# STM32H743 register map
File version: 2.4
CPU: CM7 r0p1, little endian, MPU, FPU, 4 interrupt priority bits
Registers are 32-bit, read-write, reset 0x0 unless marked. A register's access mark holds for its fields unless they carry their own. Offsets are from the block's base; [hi:lo] are bit positions; {n}, {i} and the like mark numbered series.

## ADC3 — 模数转换器
Base 0x58026000
Same registers: ADC1 0x40022000, ADC2 0x40022100
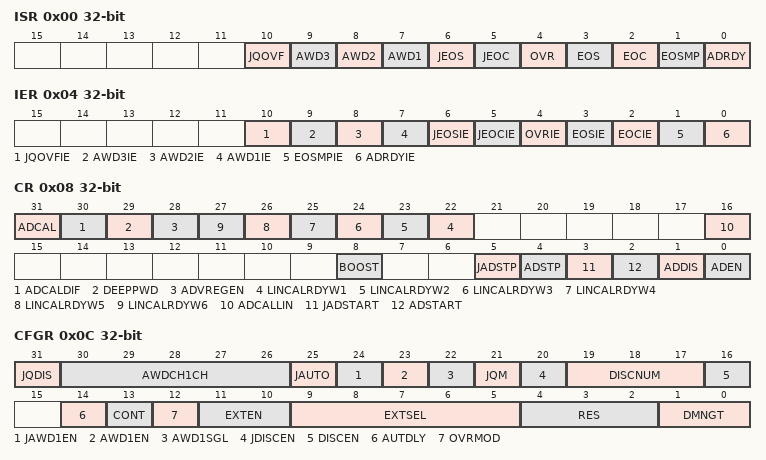
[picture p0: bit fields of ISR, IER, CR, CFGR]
0x00 ISR — ADC 中断及状态寄存器
  [10] JQOVF — ADC 注入组上下文队列溢出标志
  [9] AWD3 — ADC 模拟看门狗 3 标志
  [8] AWD2 — ADC 模拟看门狗 2 标志
  [7] AWD1 — ADC 模拟看门狗 1 标志
  [6] JEOS — ADC 注入组序列转换结束标志
  [5] JEOC — ADC 注入组单次转换结束标志
  [4] OVR — ADC 规则组溢出标志
  [3] EOS — ADC 规则组序列转换结束标志
  [2] EOC — ADC 规则组单次转换结束标志
  [1] EOSMP — ADC 规则组采样结束标志
  [0] ADRDY — ADC 就绪标志
0x04 IER — ADC 中断使能寄存器
  [10] JQOVFIE — ADC 注入组上下文队列溢出中断
  [9] AWD3IE — ADC 模拟看门狗 3 中断
  [8] AWD2IE — ADC 模拟看门狗 2 中断
  [7] AWD1IE — ADC 模拟看门狗 1 中断
  [6] JEOSIE — ADC 注入组序列转换结束中断
  [5] JEOCIE — ADC 注入组单次转换结束中断
  [4] OVRIE — ADC 规则组溢出中断
  [3] EOSIE — ADC 规则组序列转换结束中断
  [2] EOCIE — ADC 规则组单次转换结束中断
  [1] EOSMPIE — ADC 规则组采样结束中断
  [0] ADRDYIE — ADC 就绪中断
0x08 CR — ADC 控制寄存器
  [31] ADCAL — ADC 校准
  [30] ADCALDIF — ADC 差分模式校准
  [29] DEEPPWD — ADC 深度掉电使能
  [28] ADVREGEN — ADC 调压器使能
  [n+21] LINCALRDYW{n} (n=1..6) — 线性校准就绪字 {n}
  [16] ADCALLIN — 线性校准
  [8] BOOST — Boost 模式控制
  [5] JADSTP — ADC 注入组转换停止
  [4] ADSTP — ADC 规则组转换停止
  [3] JADSTART — ADC 注入组转换启动
  [2] ADSTART — ADC 规则组转换启动
  [1] ADDIS — ADC 禁用
  [0] ADEN — ADC 使能
0x0C CFGR — ADC 配置寄存器 1
  [31] JQDIS — ADC 注入组上下文队列禁用
  [30:26] AWDCH1CH — ADC 模拟看门狗 1 监测通道选择
  [25] JAUTO — ADC 注入组自动触发模式
  [24] JAWD1EN — ADC 模拟看门狗 1 注入组使能
  [23] AWD1EN — ADC 模拟看门狗 1 规则组使能
  [22] AWD1SGL — ADC 模拟看门狗 1 单通道或全通道监测选择
  [21] JQM — ADC 注入组上下文队列模式
  [20] JDISCEN — ADC 注入组序列器间断模式
  [19:17] DISCNUM — ADC 规则组序列器间断模式通道数
  [16] DISCEN — ADC 规则组序列器间断模式
  [14] AUTDLY — ADC 低功耗自动等待
  [13] CONT — ADC 规则组连续转换模式
  [12] OVRMOD — ADC 规则组溢出配置
  [11:10] EXTEN — ADC 规则组外部触发极性
  [9:5] EXTSEL — ADC 规则组外部触发源
  [4:2] RES — ADC 数据分辨率
  [1:0] DMNGT — ADC DMA 传输使能
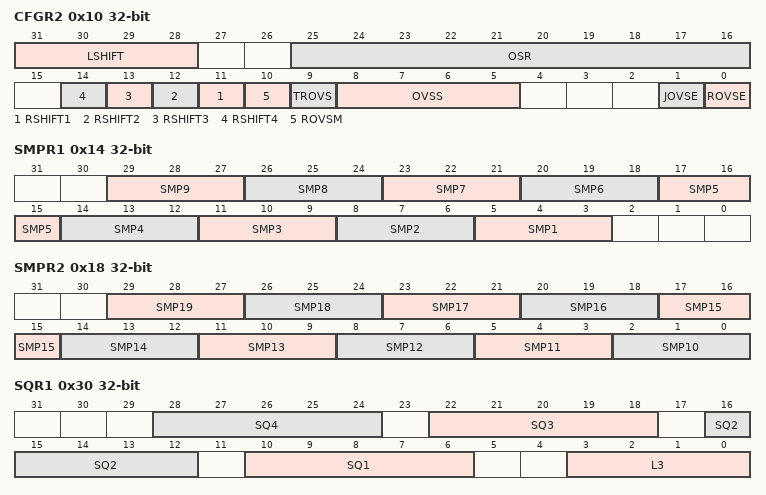
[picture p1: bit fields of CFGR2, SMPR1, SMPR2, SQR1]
0x10 CFGR2 — ADC 配置寄存器 2
  [31:28] LSHIFT — 左移因子
  [25:16] OSR — 过采样率
  [n+10] RSHIFT{n} (n=1..4) — 偏移 {n} 校正后数据右移
  [10] ROVSM — 规则组过采样模式
  [9] TROVS — ADC 规则组过采样间断模式（触发模式）
  [8:5] OVSS — ADC 过采样移位
  [1] JOVSE — ADC 注入组过采样器使能
  [0] ROVSE — ADC 规则组过采样器使能
0x14 SMPR1 — ADC 采样时间寄存器 1
  [3n+2:3n] SMP{n} (n=1..9) — ADC 通道 {n} 采样时间选择
0x18 SMPR2 — ADC 采样时间寄存器 2
  [29:27] SMP19 — ADC 通道 18 采样时间选择
  [3n-28:3n-30] SMP{n} (n=10..18) — ADC 通道 {n} 采样时间选择
0x1C PCSEL — ADC 通道预选寄存器
  [19:0] PCSEL — 通道 x (VINP[i]) 预选
0x20 LTR1 reset 0xFFF0000 — ADC 模拟看门狗 1 阈值寄存器
  [25:0] LTR1 — ADC 模拟看门狗 1 低阈值
0x24 LHTR1 reset 0xFFF0000 — ADC 模拟看门狗 2 阈值寄存器
  [25:0] LHTR1 — ADC 模拟看门狗 2 低阈值
0x30 SQR1 — ADC 规则组序列寄存器 1
  [6n+4:6n] SQ{n} (n=1..4) — ADC 规则组序列第 {n} 级
  [3:0] L3
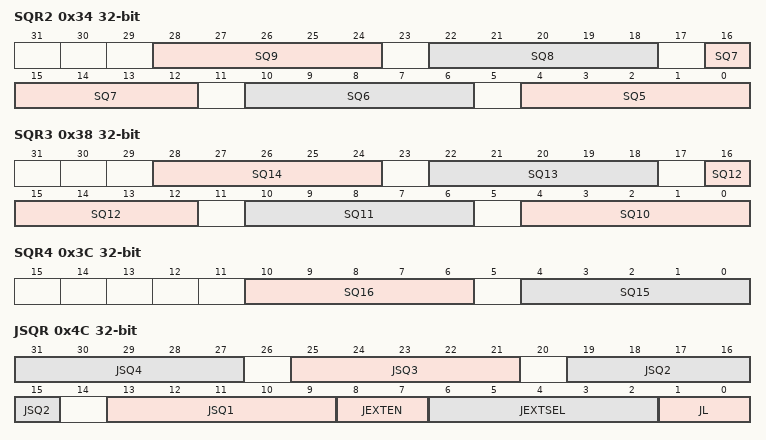
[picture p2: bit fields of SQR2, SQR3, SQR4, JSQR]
0x34 SQR2 — ADC 规则组序列寄存器 2
  [6n-26:6n-30] SQ{n} (n=5..9) — ADC 规则组序列第 {n} 级
0x38 SQR3 — ADC 规则组序列寄存器 3
  [6n-56:6n-60] SQ{n} (n=10..14) — ADC 规则组序列第 {n} 级
0x3C SQR4 — ADC 规则组序列寄存器 4
  [10:6] SQ16 — ADC 规则组序列第 16 级
  [4:0] SQ15 — ADC 规则组序列第 15 级
0x40 DR ro — ADC 规则组转换数据寄存器
  [15:0] RDATA — ADC 规则组转换数据
0x4C JSQR — ADC 注入组序列寄存器
  [6n+7:6n+3] JSQ{n} (n=1..4) — ADC 注入组序列第 {n} 级
  [8:7] JEXTEN — ADC 注入组外部触发极性
  [6:2] JEXTSEL — ADC 注入组外部触发源
  [1:0] JL — ADC 注入组序列扫描长度
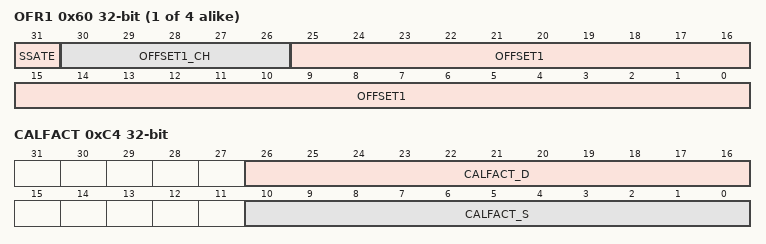
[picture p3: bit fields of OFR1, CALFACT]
{0x5C+4i} OFR{i} (i=1..4) — ADC 偏移 {i} 寄存器
  [31] SSATE — ADC 偏移 1 使能
  [30:26] OFFSET1_CH — ADC 偏移 1 通道选择
  [25:0] OFFSET1 — ADC 偏移 1 偏移量
{0x7C+4i} JDR{i} ro (i=1..4) — ADC 注入组数据寄存器 {i}
  [31:0] JDATA{i} — ADC 注入组序列第 {i} 级转换数据
0xA0 AWD2CR — ADC 模拟看门狗 2 配置寄存器
  [19:0] AWD2CH — ADC 模拟看门狗 2 监测通道选择
0xA4 AWD3CR — ADC 模拟看门狗 3 配置寄存器
  [20:1] AWD3CH — ADC 模拟看门狗 3 监测通道选择
0xB0 LTR2 — ADC 看门狗 2 低阈值寄存器
  [25:0] LTR2 — 模拟看门狗 2 低阈值
0xB4 HTR2 — ADC 看门狗 2 高阈值寄存器
  [25:0] HTR2 — 模拟看门狗 2 高阈值
0xB8 LTR3 — ADC 看门狗 3 低阈值寄存器
  [25:0] LTR3 — 模拟看门狗 3 低阈值
0xBC HTR3 — ADC 看门狗 3 高阈值寄存器
  [25:0] HTR3 — 模拟看门狗 3 高阈值
0xC0 DIFSEL — ADC 通道差分/单端模式选择寄存器
  [19:0] DIFSEL — ADC 通道差分/单端模式选择
0xC4 CALFACT — ADC 校准因子寄存器
  [26:16] CALFACT_D — ADC 差分模式校准因子
  [10:0] CALFACT_S — ADC 单端模式校准因子
0xC8 CALFACT2 — ADC 校准因子寄存器 2
  [29:0] LINCALFACT — 线性校准因子
